# AT32A403A register map
Vendor: Keil; Series: AT32A403A; File version: 1.0
CPU: CM4 r0p1, little endian, no MPU, FPU, 4 interrupt priority bits
Registers are 32-bit, read-write, reset 0x0 unless marked. A register's access mark holds for its fields unless they carry their own. Offsets are from the block's base; [hi:lo] are bit positions; 'fields as' and 'values as' point back to an identical list.

## ETHERNET_MAC — Ethernet: media access control
Base 0x40028000
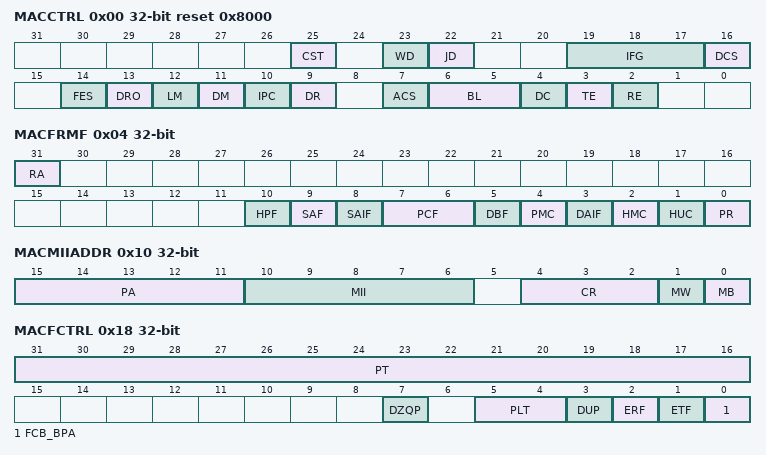
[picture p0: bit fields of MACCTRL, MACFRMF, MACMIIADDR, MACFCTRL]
0x00 MACCTRL reset 0x8000 — Ethernet MAC configuration register
  [25] CST — CRC stripping for type frames
    0=NoStrip (CRC stripping disabled); 1=StrippingEnabled (CRC stripping enabled. The last four bytes (FCS) of the Ethernet type frame is stripped before being transmitted to the application)
  [23] WD — Watchdog disable
    0=NoDisable (The MAC allows no more than 2048 bytes of the frames being received); 1=Watchdog disabled. The MAC disables the watchdog timer on the receiver, and can receive frames of up to 16,384 bytes
  [22] JD — Jabber disable
    0=NoDisable (The MAC disables the Jabber timer on the transmitter, and can transfer frames of up to 16,384 bytes); 1=Jabber disabled. The MAC allows the application to send out more than 2048 bytes of data during transmission. The MAC does not cut off the transmitter if the application sends out more than 2048 bytes of data during transmission
  [19:17] IFG — Interframe gap
    0=Ifg96Bit (Minimum interframe gap is 96 bits (12 bytes) during transmission); 1=Ifg88Bit (Minimum interframe gap is 88 bits (11 bytes) during transmission); 2=Ifg80Bit (Minimum interframe gap is 80 bits (10 bytes) during transmission); 3=Ifg72Bit (Minimum interframe gap is 72 bits (9 bytes) during transmission); 4=Ifg64Bit (Minimum interframe gap is 64 bits (8 bytes) during transmission); 5=Ifg56Bit (Minimum interframe gap is 56 bits (7 bytes) during transmission); 6=Ifg48Bit (Minimum interframe gap is 48 bits (6 bytes) during transmission); 7=Ifg40Bit (Minimum interframe gap is 40 bits (5 bytes) during transmission)
  [16] DCS — Only in half-duplex mode! Disable Carrier Sense
  [14] FES — Fast EMAC speed
    0=Speed10Mbps (The MAC operates at 10 Mbps); 1=Speed100Mbps (The MAC operates at 100 Mbps)
  [13] DRO — Only in half-duplex mode! Disable Receive Own
  [12] LM — Loopback mode
    0=NoLoopback (Loopback mode disabled); 1=Loopback mode. The MII receive clock input (clk_rx_i) is required for the loopback mode to work normally, for the transmit clock is not looped-back internally
  [11] DM — Duplex mode
    0=Half-duplex mode; 1=Full-duplex mode
  [10] IPC — IPv4 checksum offload
    0=NoIpv4Checksum (IPv4 checksum calculation disabled); 1=Ipv4ChecksumEnabled (IPv4 checksum calculation enabled)
  [9] DR — Only in half-duplex mode! Disable Retry
  [7] ACS — Automatic pad/CRC stripping
    0=NoPadCrcStripping (The MAC will forward all received frames to the master without changing its contents); 1=AutomaticPadCrcStripping (The MAC strips the pad/FCS field on received frames only when the frame length is shorter than 1536 bytes. All received frame with length field greater than or equal to 1536 bytes are passed on to the application without stripping the Pad or FCS field)
  [6:5] BL — Only in half-duplex mode! Back-off Limit
  [4] DC — Only in half-duplex mode! Deferral check
  [3] TE — Transmitter enable
    0=Disabled (Transmit disabled); 1=Enabled (Transmit enabled)
  [2] RE — Receiver enable
    0=Disabled (Receive disabled); 1=Enabled (Receive enabled)
0x04 MACFRMF — Ethernet MAC frame filter register
  [31] RA — Receive all
    0=Normal operation; 1=PassAll (Disable filters and pass all incoming frames)
  [10] HPF — Hash or perfect filter
    0=HashFilter (The MAC performs destination address filtering according to the hash table); 1=HashOrPerfectFilter (The MAC performs destination address filtering according to the hash table and perfect address filter. A frame is passed if it matches either the hash filter or the perfect address filter)
  [9] SAF — Source address filter
    0=UpdateBit (If source address filter mismatches, updates the source address filter bit (SAF) in the receive status); 1=Drop (If source address filter mismatches, frame is dropped)
  [8] SAIF — Source address inverse filtering
    0=Normal (Work normally); 1=Inverse (The address check block operates in inverse filtering mode for the source address comparison)
  [7:6] PCF — Pass control frames
    0=FilterAll (MAC filters all control frames and prevents them from reaching the application); 1=ForwardAllExceptPause (MAC forwards all control frames, except Pause frame, to the application even if they fail the address filter); 2=ForwardAll (MAC forwards all control frames to the application even if they fail the address filter); 3=ForwardFilter (MAC forwards control frames that pass the address filter to the application)
  [5] DBF — Disable broadcast frames
    0=PassBroadcast (The MAC passes all received broadcast frames to the application); 1=FilterBroadcast (The MAC filters all received broadcast frames and does not pass them to the application)
  [4] PMC — Pass multicast
    0=Normal operation; 1=PassAll (All frames with a multicast destination address (first bit in the destination address is set) are passed)
  [3] DAIF — Destination address inverse filtering
    0=Normal (Work normally); 1=Inverse (The address check block operates in inverse filtering mode for the destination address comparison for both unicast and multicast frames)
  [2] HMC — Hash multicast
    0=Disable (Direct destination address comparison for multicast); 1=EnableHash (The MAC performs destination address filtering for multicast frames according to the hash table)
  [1] HUC — Hash unicast
    0=Disable (Direct destination address comparison for unicast); 1=EnableHash (The MAC performs destination address filtering for unicast frames according to the hash table)
  [0] PR — Promiscuous mode
    0=Disable (Promiscuous mode disabled.); 1=PassAll (The MAC passes all frames to the application)
0x08 MACHTH — Ethernet MAC hash table high register
0x0C MACHTL — Ethernet MAC hash table low register
0x10 MACMIIADDR — Ethernet MAC MII address register
  [15:11] PA — PHY address
  [10:6] MII
  [4:2] CR — Clock range
    0=CsrFreq60_100 (CSR clock frequency is 60-100 MHz and MDC clock frequency is CSR/42 MHz); 1=CsrFreq100_150 (CSR clock frequency is 100-150 MHz and MDC clock frequency is CSR/62 MHz); 2=CsrFreq20_35 (CSR clock frequency is 20-35 MHz and MDC clock frequency is CSR/16 MHz); 3=CsrFreq35_60 (CSR clock frequency is 35-60 MHz and MDC clock frequency is CSR/26 MHz); 4=CsrFreq150_250 (CSR clock frequency is 150-250 MHz and MDC clock frequency is CSR/102 MHz); 5=CsrFreq250_288 (CSR clock frequency is 250-288 MHz and MDC clock frequency is CSR/124 MHz)
  [1] MW — MII write
    0=Write operation; 1=Read operation
  [0] MB — MII busy
    on read: 0=NoBusy (The MII is not busy, new operation can be started); 1=Busy (The MII is busy, operation in progress) | on write: 0=NoBusy (The MII is not busy, new operation can be started); 1=StartOperation (Start an MII operation by writing 1 to this bit. This bit is automatically cleared by hardware when the operation is completed)
0x14 MACMIIDT — Ethernet MAC MII data register
  [15:0] MD range 0..255 — MII data
0x18 MACFCTRL — Ethernet MAC flow control register
  [31:16] PT range 0..255 — Pass time
  [7] DZQP — Disable zero-quanta pause
    0=Normal operation; 1=DisableZeroQuanta (Disables the automatic generation of Zero-quanta Pause frame while the flow control signal of the FIFO layer is disabled)
  [5:4] PLT — Pause low threshold
    0=Minus4Slot (Pause time minus 4 slot times); 1=Minus28Slot (Pause time minus 28 slot times); 2=Minus144Slot (Pause time minus 144 slot times); 3=Minus256Slot (Pause time minus 256 slot times)
  [3] DUP — Detect unicast pause frame
    0=OnlyMulticast (The MAC detects only a Pause frame with a unique multicast address); 1=AnyPause (The MAC detects the Pause frames with a unicast address specified in the MAC address0 high and MAC address0 low registers)
  [2] ERF — Enable receive flow control
    0=Disabled (Receive flow control disabled); 1=Enabled (Receive flow control enabled)
  [1] ETF — Enable transmit flow control
    0=Disabled (Transmit flow control disabled); 1=Enabled (Transmit flow control enabled)
  [0] FCB_BPA write-1-sets — Flow control busy/back pressure activate
    on write: 1=InitiatePause (Initiate a pause frame. After the completion of the Pause frame, this bit resets to 0)
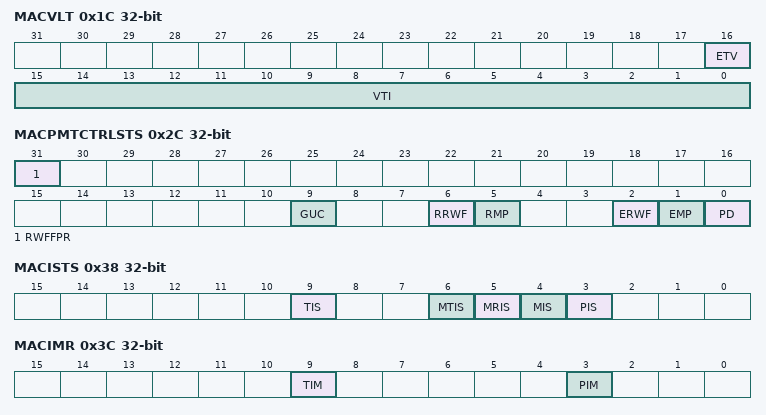
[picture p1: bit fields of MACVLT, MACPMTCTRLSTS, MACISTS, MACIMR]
0x1C MACVLT — Ethernet MAC VLAN tag register
  [16] ETV — Enable 12-bit VLAN tag comparison
    0=Normal16bit (Full 16-bit VLAN tag is used for filtering); 1=Compressed12bit (12-bit VLAN tag is used for comparison and filtering.)
  [15:0] VTI range 0..255 — VLAN tag identifier (for receive frames)
0x28 MACRWFF — Ethernet MAC remote wakeup frame filter register
0x2C MACPMTCTRLSTS — Ethernet MAC PMT control and status register
  [31] RWFFPR write-1-sets — Remote wakeup frame filter register pointer reset
    on write: 1=ResetPointer (Resets the remote frame filter register pointer to 3’b000)
  [9] GUC — Global unicast
    0=Disable (Normal operation); 1=GlobalUnicast (All unicast packets filtered by the MAC address filters are treated as wakeup frames. If any of these packets is received, a PMT event is generated)
  [6] RRWF ro read-clears — Received remote wakeup frame
    0=NoWakeup (No remote wakeup frame has been received since the last read of this register); 1=WakeupReceived (Remote wakeup frame has been received since the last read of this register)
  [5] RMP ro read-clears — Received magic packet
    0=No Magic Packet has been received since the last read of this register; 1=MagicPacketReceived (Magic Packet has been received since the last read of this register)
  [2] ERWF — Enable remote wakeup frame
    0=Disable remote wakeup frame detection; 1=Enable remote wakeup frame detection. Power management event is generated when a remote wakeup frame is received.
  [1] EMP — Enable magic packet
    0=Disable magic packet detection; 1=Enable magic packet detection. Power management event is generated when a magic packet is received.
  [0] PD write-1-sets — Power down
    on write: 1=Power down. Power back up when receive expected Magic packet or clear this bit
0x38 MACISTS — Ethernet MAC interrupt status register
  [9] TIS ro read-clears — Timestamp interrupt status
    0=No timestamp interrupt; 1=TimestampInterrupt (System time value equals or exceeds the value programmed in the destination time registers)
  [6] MTIS ro — MMC transmit interrupt status
    0=No MMC transmit interrupt; 1=MmcTransmitInterrupt (Interrupt event is generated in the EMAC_MMCTI register.)
  [5] MRIS ro — MMC receive interrupt status
    0=No MMC receive interrupt; 1=MmcReceiveInterrupt (Interrupt event is generated in the EMAC_MMCRI register.)
  [4] MIS ro — MMC interrupt status
    0=No MMC interrupt; 1=MmcInterrupt (Interrupt event is generated in the EMAC_MMCRI or EMAC_MMCTI register.)
  [3] PIS ro — PMT interrupt status
    0=No PMT interrupt; 1=PmtInterrupt (Magic packet or a remote wakeup event is received in power-down mode)
0x3C MACIMR — Ethernet MAC interrupt mask register
  [9] TIM — Timestamp interrupt mask
    0=InterruptDisabled (Timestamp interrupt is disabled); 1=InterruptEnabled (Timestamp interrupt is enabled)
  [3] PIM — PMT interrupt mask
    0=InterruptDisabled (PMT interrupt is disabled); 1=InterruptEnabled (PMT interrupt is enabled)
0x40 MACA0H reset 0xFFFF — Ethernet MAC address 0 high register. This register changed to 16 bits wide, because the only available another field is bit 31 - AE, but it is restricted to be always 1.
  [15:0] MA0H — MAC address0 high
0x44 MACA0L reset 0xFFFFFFFF — Ethernet MAC address 0 low register
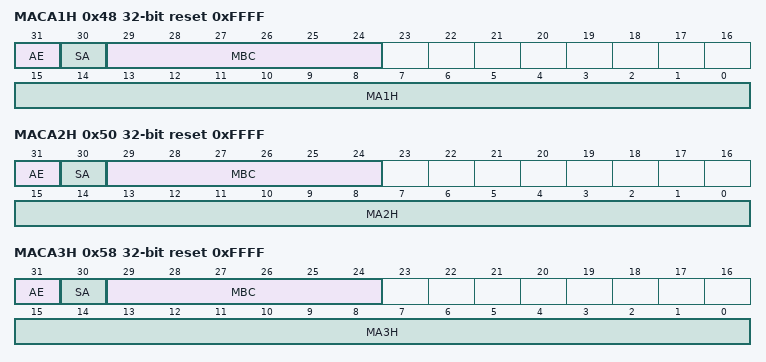
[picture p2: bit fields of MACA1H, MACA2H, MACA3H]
0x48 MACA1H reset 0xFFFF — Ethernet MAC address 1 high register
  [31] AE — Address enable
    0=Disabled (Second MAC address filter is disabled); 1=Enabled (Second MAC address filter is enabled)
  [30] SA — Source address
    0=Source (Second MAC address filter is used for source address filtering); 1=Destination (Second MAC address filter is used for destination address filtering)
  [29:24] MBC — Mask byte control
  [15:0] MA1H — MAC address1 high
0x4C MACA1L reset 0xFFFFFFFF — Ethernet MAC address1 low register
0x50 MACA2H reset 0xFFFF — Ethernet MAC address 2 high register
  [31] AE — Address enable
    values as MACA1H.AE
  [30] SA — Source address
    values as MACA1H.SA
  [29:24] MBC — Mask byte control
  [15:0] MA2H — MAC address 2 high
0x54 MACA2L reset 0xFFFFFFFF — Ethernet MAC address 2 low register
0x58 MACA3H reset 0xFFFF — Ethernet MAC address 3 high register
  [31] AE — Address enable
    values as MACA1H.AE
  [30] SA — Source address
    values as MACA1H.SA
  [29:24] MBC — Mask byte control
  [15:0] MA3H — MAC address3 high
0x5C MACA3L reset 0xFFFFFFFF — Ethernet MAC address 3 low register
